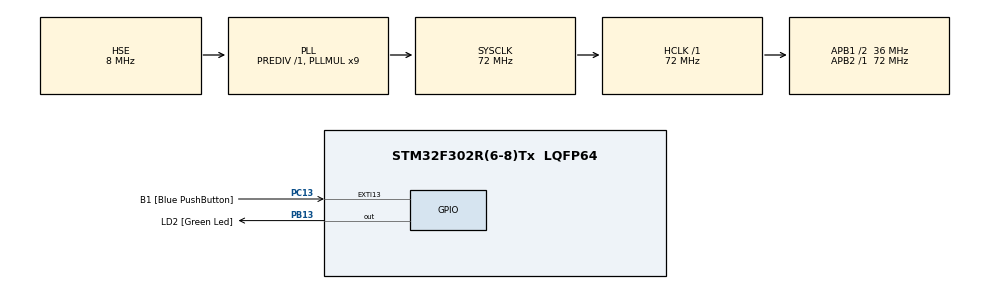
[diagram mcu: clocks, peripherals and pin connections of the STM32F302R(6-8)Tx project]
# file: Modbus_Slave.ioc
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Mcu.Family=STM32F3
Mcu.Name=STM32F302R(6-8)Tx
Mcu.Package=LQFP64
NVIC.PriorityGroup=NVIC_PRIORITYGROUP_0
PA13.GPIO_Label=TMS
PA13.Mode=Serial_Wire
PA13.Signal=SYS_JTMS-SWDIO
PA14.GPIO_Label=TCK
PA14.Mode=Serial_Wire
PA14.Signal=SYS_JTCK-SWCLK
PB13.GPIO_Label=LD2 [Green Led]
PB13.Signal=GPIO_Output
PB3.GPIO_Label=SWO
PB3.Mode=Trace_Asynchronous_SW
PB3.Signal=SYS_JTDO-TRACESWO
PC13.GPIO_Label=B1 [Blue PushButton]
PC13.GPIO_ModeDefaultEXTI=GPIO_MODE_IT_FALLING
PC13.Signal=GPXTI13
PC14\ -\ OSC32_IN.Mode=LSE-External-Oscillator
PC14\ -\ OSC32_IN.Signal=RCC_OSC32_IN
PC15\ -\ OSC32_OUT.Mode=LSE-External-Oscillator
PC15\ -\ OSC32_OUT.Signal=RCC_OSC32_OUT
PC4.Signal=USART1_TX
PC5.Signal=USART1_RX
PF0-OSC_IN.Mode=HSE-External-Clock-Source
PF0-OSC_IN.Signal=RCC_OSC_IN
PF1-OSC_OUT.Signal=RCC_OSC_OUT
ProjectManager.HeapSize=0x200
ProjectManager.StackSize=0x400
ProjectManager.TargetToolchain=STM32CubeIDE
RCC.AHBFreq_Value=72000000
RCC.APB1CLKDivider=RCC_HCLK_DIV2
RCC.APB1Freq_Value=36000000
RCC.APB1TimFreq_Value=72000000
RCC.APB2Freq_Value=72000000
RCC.APB2TimFreq_Value=72000000
RCC.CortexFreq_Value=72000000
RCC.HCLKFreq_Value=72000000
RCC.HSE_VALUE=8000000
RCC.HSI_VALUE=8000000
RCC.PLLM=8
RCC.PLLMUL=RCC_PLL_MUL9
RCC.PLLN=336
RCC.PLLP=RCC_PLLP_DIV4
RCC.PLLQ=7
RCC.PLLSourceVirtual=RCC_PLLSOURCE_HSE
RCC.SYSCLKFreq_VALUE=72000000
RCC.SYSCLKSourceVirtual=RCC_SYSCLKSOURCE_PLLCLK
RCC.USBFreq_Value=72000000
board=NUCLEO-F302R8

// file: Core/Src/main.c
/* USER CODE BEGIN Header */
/**
  ******************************************************************************
  * @file           : main.c
  * @brief          : Main program body
  ******************************************************************************
  * @attention
  *
  * Copyright (c) 2022 STMicroelectronics.
  * All rights reserved.
  *
  * This software is licensed under terms that can be found in the LICENSE file
  * in the root directory of this software component.
  * If no LICENSE file comes with this software, it is provided AS-IS.
  *
  ******************************************************************************
  */
/* USER CODE END Header */
#include "main.h"

/* USER CODE BEGIN PTD */
typedef union modbusData {
	uint8_t all[10];
	struct {
		uint16_t reg1;
		uint16_t reg2;
		uint16_t reg3;
		uint16_t reg4;
		uint16_t reg5;
	};
}modbusData;
/* USER CODE END PTD */

/* USER CODE BEGIN PV */

 modbus_t modbus;
 modbusData modbus_data = {{0x01, 0x02, 0x30, 0x40, 0x05, 0x06, 0x07, 0x08, 0x09, 0x10}};
 uint8_t registers[10];

/* USER CODE END PV */

void SystemClock_Config(void);
static void MX_GPIO_Init(void);

int main(void)
{

  /* MCU Configuration--------------------------------------------------------*/

  /* Reset of all peripherals, Initializes the Flash interface and the Systick. */
  HAL_Init();

  /* Configure the system clock */
  SystemClock_Config();

  /* Initialize all configured peripherals */
  MX_GPIO_Init();
  /* USER CODE BEGIN 2 */

  modbus_tx_buffer_init();
  modbus_rx_buffer_init() ;
  modbus_uart_init();
  modbus_timer_init();
  modbus_crc_init();

  modbus_init(&modbus);
  modbus_receive_start(&modbus);

//  modbus.buffer[0] = 0x01;
//  modbus.buffer[1] = 0x06;
//  modbus.buffer[2] = 0x00;
//  modbus.buffer[3] = 0x01;
//  modbus.buffer[4] = 0x00;
//  modbus.buffer[5] = 0x30;
//  modbus.buffer[6] = 0xD8;
//  modbus.buffer[7] = 0x1E;
//  modbus_transmite_start(&modbus, 8);

  uint32_t timer = HAL_GetTick();
  /* USER CODE END 2 */

  /* Infinite loop */
  /* USER CODE BEGIN WHILE */
  while (1)
  {
	  modbus_handler(&modbus, modbus_data.all, 10);
	  if(HAL_GetTick() - timer > 1000) {
		  timer = HAL_GetTick();
		  modbus_data.reg1 = modbus_data.reg1 + 1;
	  }

    /* USER CODE END WHILE */

  }
}

void SystemClock_Config(void)
{
  RCC_OscInitTypeDef RCC_OscInitStruct = {0};
  RCC_ClkInitTypeDef RCC_ClkInitStruct = {0};

  /** Initializes the RCC Oscillators according to the specified parameters
  * in the RCC_OscInitTypeDef structure.
  */
  RCC_OscInitStruct.OscillatorType = RCC_OSCILLATORTYPE_HSE;
  RCC_OscInitStruct.HSEState = RCC_HSE_BYPASS;
  RCC_OscInitStruct.HSEPredivValue = RCC_HSE_PREDIV_DIV1;
  RCC_OscInitStruct.HSIState = RCC_HSI_ON;
  RCC_OscInitStruct.PLL.PLLState = RCC_PLL_ON;
  RCC_OscInitStruct.PLL.PLLSource = RCC_PLLSOURCE_HSE;
  RCC_OscInitStruct.PLL.PLLMUL = RCC_PLL_MUL9;
  if (HAL_RCC_OscConfig(&RCC_OscInitStruct) != HAL_OK)
  {
    Error_Handler();
  }

  /** Initializes the CPU, AHB and APB buses clocks
  */
  RCC_ClkInitStruct.ClockType = RCC_CLOCKTYPE_HCLK|RCC_CLOCKTYPE_SYSCLK
                              |RCC_CLOCKTYPE_PCLK1|RCC_CLOCKTYPE_PCLK2;
  RCC_ClkInitStruct.SYSCLKSource = RCC_SYSCLKSOURCE_PLLCLK;
  RCC_ClkInitStruct.AHBCLKDivider = RCC_SYSCLK_DIV1;
  RCC_ClkInitStruct.APB1CLKDivider = RCC_HCLK_DIV2;
  RCC_ClkInitStruct.APB2CLKDivider = RCC_HCLK_DIV1;

  if (HAL_RCC_ClockConfig(&RCC_ClkInitStruct, FLASH_LATENCY_2) != HAL_OK)
  {
    Error_Handler();
  }
}

static void MX_GPIO_Init(void)
{
  GPIO_InitTypeDef GPIO_InitStruct = {0};

  /* GPIO Ports Clock Enable */
  __HAL_RCC_GPIOC_CLK_ENABLE();
  __HAL_RCC_GPIOF_CLK_ENABLE();
  __HAL_RCC_GPIOB_CLK_ENABLE();
  __HAL_RCC_GPIOA_CLK_ENABLE();

  /*Configure GPIO pin Output Level */
  HAL_GPIO_WritePin(LD2_GPIO_Port, LD2_Pin, GPIO_PIN_RESET);

  /*Configure GPIO pin : B1_Pin */
  GPIO_InitStruct.Pin = B1_Pin;
  GPIO_InitStruct.Mode = GPIO_MODE_IT_FALLING;
  GPIO_InitStruct.Pull = GPIO_NOPULL;
  HAL_GPIO_Init(B1_GPIO_Port, &GPIO_InitStruct);

  /*Configure GPIO pins : PC4 PC5 */
  GPIO_InitStruct.Pin = GPIO_PIN_4|GPIO_PIN_5;
  GPIO_InitStruct.Mode = GPIO_MODE_AF_PP;
  GPIO_InitStruct.Pull = GPIO_NOPULL;
  GPIO_InitStruct.Speed = GPIO_SPEED_FREQ_HIGH;
  GPIO_InitStruct.Alternate = GPIO_AF7_USART1;
  HAL_GPIO_Init(GPIOC, &GPIO_InitStruct);

  /*Configure GPIO pin : LD2_Pin */
  GPIO_InitStruct.Pin = LD2_Pin;
  GPIO_InitStruct.Mode = GPIO_MODE_OUTPUT_PP;
  GPIO_InitStruct.Pull = GPIO_NOPULL;
  GPIO_InitStruct.Speed = GPIO_SPEED_FREQ_LOW;
  HAL_GPIO_Init(LD2_GPIO_Port, &GPIO_InitStruct);

}

void Error_Handler(void)
{
  __disable_irq();
  while (1)
  {
  }
}
